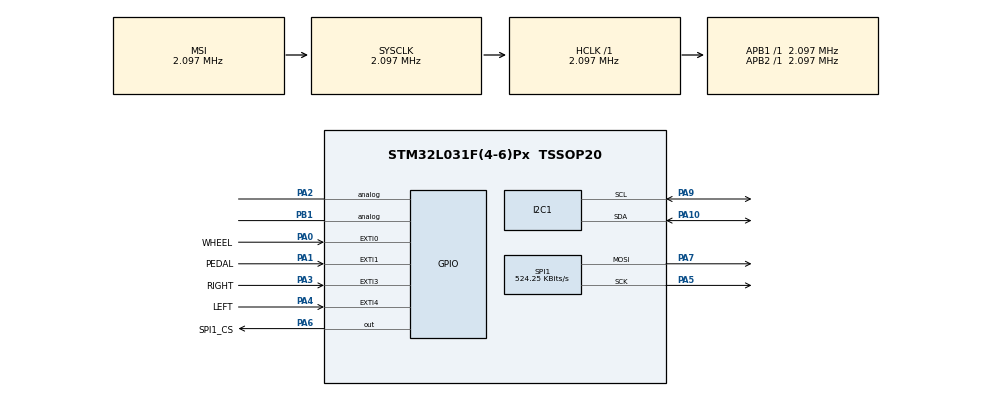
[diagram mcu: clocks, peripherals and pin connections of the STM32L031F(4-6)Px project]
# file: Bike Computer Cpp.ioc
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I2C1.Speed=50
I2C1.Timing=0x0000061E
Mcu.Family=STM32L0
Mcu.Name=STM32L031F(4-6)Px
Mcu.Package=TSSOP20
NVIC.EXTI0_1_IRQn=true\:0\:0\:false\:false\:true\:true\:true\:true
NVIC.EXTI2_3_IRQn=true\:0\:0\:false\:false\:true\:true\:true\:true
NVIC.EXTI4_15_IRQn=true\:0\:0\:false\:false\:true\:true\:true\:true
NVIC.RTC_IRQn=true\:0\:0\:false\:false\:true\:true\:true\:true
PA0-CK_IN.GPIO_Label=WHEEL
PA0-CK_IN.GPIO_ModeDefaultEXTI=GPIO_MODE_IT_FALLING
PA0-CK_IN.GPIO_PuPd=GPIO_PULLUP
PA0-CK_IN.Signal=GPXTI0
PA1.GPIO_Label=PEDAL
PA1.GPIO_ModeDefaultEXTI=GPIO_MODE_IT_FALLING
PA1.GPIO_PuPd=GPIO_PULLUP
PA1.Signal=GPXTI1
PA10.GPIO_Pu=GPIO_PULLUP
PA10.Mode=I2C
PA10.Signal=I2C1_SDA
PA13.Mode=Serial_Wire
PA13.Signal=SYS_SWDIO
PA14.Mode=Serial_Wire
PA14.Signal=SYS_SWCLK
PA2.Signal=GPIO_Analog
PA3.GPIO_Label=RIGHT
PA3.GPIO_ModeDefaultEXTI=GPIO_MODE_IT_FALLING
PA3.GPIO_PuPd=GPIO_PULLUP
PA3.Signal=GPXTI3
PA4.GPIO_Label=LEFT
PA4.GPIO_ModeDefaultEXTI=GPIO_MODE_IT_FALLING
PA4.GPIO_PuPd=GPIO_PULLUP
PA4.Signal=GPXTI4
PA5.Mode=TX_Only_Simplex_Unidirect_Master
PA5.Signal=SPI1_SCK
PA6.GPIO_Label=SPI1_CS
PA6.Signal=GPIO_Output
PA7.Mode=TX_Only_Simplex_Unidirect_Master
PA7.Signal=SPI1_MOSI
PA9.GPIO_Pu=GPIO_PULLUP
PA9.Mode=I2C
PA9.Signal=I2C1_SCL
PB1.Signal=GPIO_Analog
PC14-OSC32_IN.Mode=LSE-External-Oscillator
PC14-OSC32_IN.Signal=RCC_OSC32_IN
PC15-OSC32_OUT.Mode=LSE-External-Oscillator
PC15-OSC32_OUT.Signal=RCC_OSC32_OUT
ProjectManager.HeapSize=0x200
ProjectManager.StackSize=0x400
ProjectManager.TargetToolchain=STM32CubeIDE
RCC.AHBFreq_Value=2097000
RCC.APB1Freq_Value=2097000
RCC.APB1TimFreq_Value=2097000
RCC.APB2Freq_Value=2097000
RCC.APB2TimFreq_Value=2097000
RCC.HCLKFreq_Value=2097000
RCC.HSE_VALUE=8000000
RCC.HSI16_VALUE=16000000
RCC.HSI_VALUE=16000000
RCC.LptimClockSelection=RCC_LPTIM1CLKSOURCE_LSE
RCC.MSI_VALUE=2097000
RCC.PLLDIV=RCC_PLLDIV_4
RCC.PLLMUL=RCC_PLLMUL_4
RCC.RTCClockSelectionVirtual=RCC_RTCCLKSOURCE_LSE
RCC.SYSCLKFreq_VALUE=2097000
RCC.VCOOutputFreq_Value=64000000
RTC.AsynchPrediv=127
RTC.SynchPrediv=255
RTC.WakeUpClock-WakeUp=RTC_WAKEUPCLOCK_CK_SPRE_16BITS
RTC.WakeUpCounter-WakeUp=59
SPI1.BaudRatePrescaler=SPI_BAUDRATEPRESCALER_4
SPI1.CalculateBaudRate=524.25 KBits/s
SPI1.Direction=SPI_DIRECTION_2LINES
SPI1.FirstBit=SPI_FIRSTBIT_LSB
SPI1.Mode=SPI_MODE_MASTER
SPI1.VirtualType=VM_MASTER
VP_RTC_VS_RTC_Activate.Mode=RTC_Enabled
VP_RTC_VS_RTC_Calendar.Mode=RTC_Calendar
VP_RTC_VS_RTC_WakeUp_intern.Mode=WakeUp
board=custom

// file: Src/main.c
/* USER CODE BEGIN Header */
/**
  ******************************************************************************
  * @file           : main.c
  * @brief          : Main program body
  ******************************************************************************
  * @attention
  *
  * Copyright (c) 2023 STMicroelectronics.
  * All rights reserved.
  *
  * This software is licensed under terms that can be found in the LICENSE file
  * in the root directory of this software component.
  * If no LICENSE file comes with this software, it is provided AS-IS.
  *
  ******************************************************************************
  */
/* USER CODE END Header */
#include "main.h"
#include "i2c.h"
#include "rtc.h"
#include "spi.h"
#include "gpio.h"

/* USER CODE BEGIN Includes */
#include "alt_main.h"

/* USER CODE END Includes */

void SystemClock_Config(void);

int main(void)
{

  /* MCU Configuration--------------------------------------------------------*/

  /* Reset of all peripherals, Initializes the Flash interface and the Systick. */
  HAL_Init();

  /* Configure the system clock */
  SystemClock_Config();

  /* Initialize all configured peripherals */
  MX_GPIO_Init();
  MX_SPI1_Init();
  MX_RTC_Init();
  MX_I2C1_Init();

  /* Infinite loop */
  /* USER CODE BEGIN WHILE */
  alt_main(); // Contains our super loop, so the while loop below will never be executed
  while (1)
  {
    /* USER CODE END WHILE */

  }
}

void SystemClock_Config(void)
{
  RCC_OscInitTypeDef RCC_OscInitStruct = {0};
  RCC_ClkInitTypeDef RCC_ClkInitStruct = {0};
  RCC_PeriphCLKInitTypeDef PeriphClkInit = {0};

  /** Configure the main internal regulator output voltage
  */
  __HAL_PWR_VOLTAGESCALING_CONFIG(PWR_REGULATOR_VOLTAGE_SCALE1);

  /** Configure LSE Drive Capability
  */
  HAL_PWR_EnableBkUpAccess();
  __HAL_RCC_LSEDRIVE_CONFIG(RCC_LSEDRIVE_LOW);

  /** Initializes the RCC Oscillators according to the specified parameters
  * in the RCC_OscInitTypeDef structure.
  */
  RCC_OscInitStruct.OscillatorType = RCC_OSCILLATORTYPE_LSE|RCC_OSCILLATORTYPE_MSI;
  RCC_OscInitStruct.LSEState = RCC_LSE_ON;
  RCC_OscInitStruct.MSIState = RCC_MSI_ON;
  RCC_OscInitStruct.MSICalibrationValue = 0;
  RCC_OscInitStruct.MSIClockRange = RCC_MSIRANGE_5;
  RCC_OscInitStruct.PLL.PLLState = RCC_PLL_NONE;
  if (HAL_RCC_OscConfig(&RCC_OscInitStruct) != HAL_OK)
  {
    Error_Handler();
  }

  /** Initializes the CPU, AHB and APB buses clocks
  */
  RCC_ClkInitStruct.ClockType = RCC_CLOCKTYPE_HCLK|RCC_CLOCKTYPE_SYSCLK
                              |RCC_CLOCKTYPE_PCLK1|RCC_CLOCKTYPE_PCLK2;
  RCC_ClkInitStruct.SYSCLKSource = RCC_SYSCLKSOURCE_MSI;
  RCC_ClkInitStruct.AHBCLKDivider = RCC_SYSCLK_DIV1;
  RCC_ClkInitStruct.APB1CLKDivider = RCC_HCLK_DIV1;
  RCC_ClkInitStruct.APB2CLKDivider = RCC_HCLK_DIV1;

  if (HAL_RCC_ClockConfig(&RCC_ClkInitStruct, FLASH_LATENCY_0) != HAL_OK)
  {
    Error_Handler();
  }
  PeriphClkInit.PeriphClockSelection = RCC_PERIPHCLK_I2C1|RCC_PERIPHCLK_RTC;
  PeriphClkInit.I2c1ClockSelection = RCC_I2C1CLKSOURCE_PCLK1;
  PeriphClkInit.RTCClockSelection = RCC_RTCCLKSOURCE_LSE;
  if (HAL_RCCEx_PeriphCLKConfig(&PeriphClkInit) != HAL_OK)
  {
    Error_Handler();
  }
}

void Error_Handler(void)
{
  __disable_irq();
  while (1)
  {
  }
}
